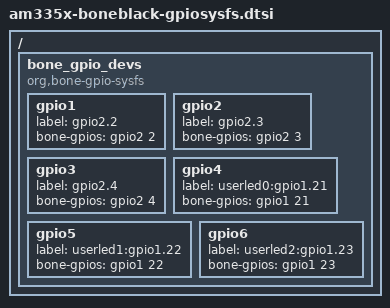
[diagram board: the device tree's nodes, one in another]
/{
	bone_gpio_devs {
		compatible = "org,bone-gpio-sysfs";

		gpio1{
			label = "gpio2.2"; /*GPIO2 PIN2*/
			bone-gpios = <&gpio2 2 GPIO_ACTIVE_HIGH>;
		};
		gpio2{
			label = "gpio2.3";
			bone-gpios = <&gpio2 3 GPIO_ACTIVE_HIGH>;
		};
		gpio3{
			label = "gpio2.4";
			bone-gpios = <&gpio2 4 GPIO_ACTIVE_HIGH>;
		};
		gpio4{
			label = "userled0:gpio1.21";
			bone-gpios = <&gpio1 21 GPIO_ACTIVE_HIGH>;
		};
		gpio5{
			label = "userled1:gpio1.22";
			bone-gpios = <&gpio1 22 GPIO_ACTIVE_HIGH>;
		};
		gpio6{
			label = "userled2:gpio1.23";
			bone-gpios = <&gpio1 23 GPIO_ACTIVE_HIGH>;
		};
	};
};
